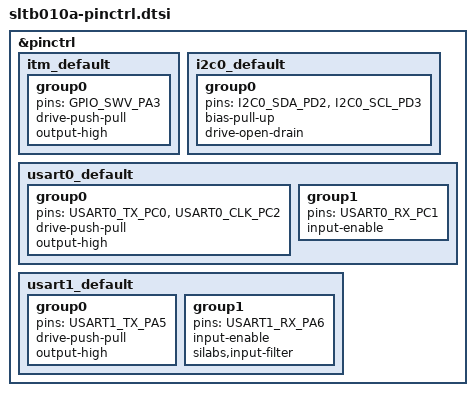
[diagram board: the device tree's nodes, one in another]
/*
 * Copyright (c) 2024 Silicon Laboratories Inc.
 *
 * SPDX-License-Identifier: Apache-2.0
 */

#include <zephyr/dt-bindings/pinctrl/silabs/xg22-pinctrl.h>

&pinctrl {
	itm_default: itm_default {
		group0 {
			pins = <GPIO_SWV_PA3>;
			drive-push-pull;
			output-high;
		};
	};

	i2c0_default: i2c0_default {
		group0 {
			pins = <I2C0_SDA_PD2>, <I2C0_SCL_PD3>;
			bias-pull-up;
			drive-open-drain;
		};
	};

	usart0_default: usart0_default {
		group0 {
			pins = <USART0_TX_PC0>, <USART0_CLK_PC2>;
			drive-push-pull;
			output-high;
		};

		group1 {
			pins = <USART0_RX_PC1>;
			input-enable;
		};
	};

	usart1_default: usart1_default {
		group0 {
			pins = <USART1_TX_PA5>;
			drive-push-pull;
			output-high;
		};

		group1 {
			pins = <USART1_RX_PA6>;
			input-enable;
			silabs,input-filter;
		};
	};
};
